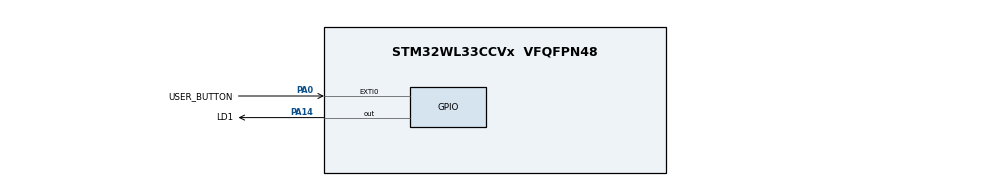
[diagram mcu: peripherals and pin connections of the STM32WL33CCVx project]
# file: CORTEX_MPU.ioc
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Mcu.Family=STM32WL3
Mcu.Name=STM32WL33CCVx
Mcu.Package=VFQFPN48
NVIC.GPIOA_IRQn=true\:0\:0\:false\:false\:true\:true\:true\:true
OSCIN.Mode=HSE-External-Oscillator
OSCIN.Signal=RCC_OSC_IN
OSCOUT.Mode=HSE-External-Oscillator
OSCOUT.Signal=RCC_OSC_OUT
PA0.GPIO_Label=USER_BUTTON
PA0.GPIO_ModeDefaultEXTI=GPIO_MODE_IT_FALLING
PA0.GPIO_PuPd=GPIO_PULLUP
PA0.Signal=GPXTI0
PA14.GPIO_Label=LD1
PA14.GPIO_ModeDefaultOutputPP=GPIO_MODE_OUTPUT_PP
PA14.GPIO_Speed=GPIO_SPEED_FREQ_VERY_HIGH
PA14.Signal=GPIO_Output
ProjectManager.HeapSize=0x000
ProjectManager.StackSize=0xC00
ProjectManager.TargetToolchain=EWARM V9.30
RCC.HSE_VALUE=48000000
RCC.HSI_VALUE=64000000
RCC.LSE_VALUE=32768
RCC.RC64MPLLSource=RCC_LSCOSOURCE_PLL64
VP_PWR_VS_SECSignals.Mode=Security/Privilege
board=custom

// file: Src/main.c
/* USER CODE BEGIN Header */
/**
  ******************************************************************************
  * @file    Examples_LL/CORTEX/CORTEX_MPU/Src/main.c
  * @author  MCD Application Team
  * @brief   This example presents the MPU features through
  *          the STM32WL3x CORTEX LL API.
  ******************************************************************************
  * @attention
  *
  * Copyright (c) 2024 STMicroelectronics.
  * All rights reserved.
  *
  * This software is licensed under terms that can be found in the LICENSE file
  * in the root directory of this software component.
  * If no LICENSE file comes with this software, it is provided AS-IS.
  *
  ******************************************************************************
  */
/* USER CODE END Header */
#include "main.h"

/* USER CODE BEGIN PD */

/* Address of the privileged read-only area */
#define ARRAY_ADDRESS_START                      (0x20002000UL)
/* Size of privileged read-only area */
#define ARRAY_SIZE                               LL_MPU_REGION_SIZE_512B
/* Region size to contain privileged read-only area */
#define REGION_SIZE                              LL_MPU_REGION_SIZE_256B
#define REGION_NUMBER                            LL_MPU_REGION_NUMBER3
#define EXAMPLE_RAM_ADDRESS_START                (0x20000000UL)
#define EXAMPLE_RAM_SIZE                         LL_MPU_REGION_SIZE_16KB
#define EXAMPLE_PERIPH_ADDRESS_START             (0x40000000)
#define EXAMPLE_PERIPH_SIZE                      LL_MPU_REGION_SIZE_512KB
#define EXAMPLE_FLASH_ADDRESS_START              (0x08000000)
#define EXAMPLE_FLASH_SIZE                       LL_MPU_REGION_SIZE_512KB
#define EXAMPLE_RAM_REGION_NUMBER                LL_MPU_REGION_NUMBER0
#define EXAMPLE_FLASH_REGION_NUMBER              LL_MPU_REGION_NUMBER1
#define EXAMPLE_PERIPH_REGION_NUMBER             LL_MPU_REGION_NUMBER2
#define portMPU_REGION_READ_WRITE                LL_MPU_REGION_FULL_ACCESS
#define portMPU_REGION_PRIVILEGED_READ_ONLY      LL_MPU_REGION_PRIV_RO
#define portMPU_REGION_READ_ONLY                 LL_MPU_REGION_PRIV_RO_URO
#define portMPU_REGION_PRIVILEGED_READ_WRITE     LL_MPU_REGION_PRIV_RW

/* USER CODE END PD */

/* USER CODE BEGIN PV */

__IO uint8_t ubButtonPress = 0;

#if defined ( __ICCARM__ )
#pragma location=ARRAY_ADDRESS_START
__no_init __IO uint8_t PrivilegedReadOnlyArray[ARRAY_SIZE];
#else
__IO uint8_t PrivilegedReadOnlyArray[ARRAY_SIZE] __attribute__((section(".ROarraySection")));
#endif

/* USER CODE END PV */

void SystemClock_Config(void);
void PeriphCommonClock_Config(void);
static void MX_GPIO_Init(void);
/* USER CODE BEGIN PFP */

void     Configure_MPU(void);
void     MPU_AccessPermConfig(void);
void LED_On(void);
void LED_Off(void);
void WaitForUserButtonPress(void);

/* USER CODE END PFP */

int main(void)
{

  /* MCU Configuration--------------------------------------------------------*/

  /* Reset of all peripherals, Initializes the Flash interface and the Systick. */
  LL_APB0_GRP1_EnableClock(LL_APB0_GRP1_PERIPH_SYSCFG);

  /* Configure the system clock */
  SystemClock_Config();

  /* Configure the peripherals common clocks */
  PeriphCommonClock_Config();

  /* Initialize all configured peripherals */
  MX_GPIO_Init();
  /* USER CODE BEGIN 2 */

  /* Set MPU regions */
  Configure_MPU();
  MPU_AccessPermConfig();

  /* Read from PrivilegedReadOnlyArray. This will not generate error */
  (void)PrivilegedReadOnlyArray[ARRAY_SIZE - 1];

  /* Toggle quickly LD1 while waiting for User-button press */
  WaitForUserButtonPress();

  /* Write into PrivilegedReadOnlyArray. This will generate memory fault error */
  PrivilegedReadOnlyArray[ARRAY_SIZE - 1] = 'e';

  /* USER CODE END 2 */

  /* Infinite loop */
  while (1)
  {

  }
}

void SystemClock_Config(void)
{

   /* Set HSE Capacitor Tuning */
  LL_RCC_HSE_SetCapacitorTuning(CFG_HW_RCC_HSE_CAPACITOR_TUNE);

   /* Set HSE startup Current */
 LL_RCC_HSE_SetStartupCurrent(0);

   /* Set HSE Amplitude Threshold */
 LL_RCC_HSE_SetAmplitudeThreshold(0);

   /* Set HSE Current Control */
  LL_RCC_HSE_SetCurrentControl(40);

   /* Enable the HSE */
  LL_RCC_HSE_Enable();

   /* Wait till HSE is ready */
  while(LL_RCC_HSE_IsReady() != 1)
  {
  }

  LL_FLASH_SetLatency(LL_FLASH_WAIT_STATES_1);

   /* Enable the RC64MPLL*/
  LL_RCC_RC64MPLL_Enable();

   /* Wait till RC64MPLL is ready */
  while(LL_RCC_RC64MPLL_IsReady() != 1)
  {
  }

  LL_RCC_SetRC64MPLLPrescaler(LL_RCC_RC64MPLL_DIV_1);

   /* Update the SystemCoreClock global variable */
  LL_SetSystemCoreClock(64000000);

   /* Configure the source of time base considering new system clocks settings*/
  LL_Init1msTick(64000000);
}

void PeriphCommonClock_Config(void)
{
  LL_RCC_SetSMPSPrescaler(LL_RCC_SMPS_DIV_2);

   /* Enable the KRM*/
  LL_RCC_KRM_Enable();
  LL_RCC_KRM_SetRateMultiplier(2);
}

static void MX_GPIO_Init(void)
{
  LL_GPIO_InitTypeDef GPIO_InitStruct = {0};

  /* GPIO Ports Clock Enable */
  LL_AHB1_GRP1_EnableClock(LL_AHB1_GRP1_PERIPH_GPIOA);

  /**/
  LL_GPIO_ResetOutputPin(LD1_GPIO_Port, LD1_Pin);

  /**/
  LL_GPIO_SetPinPull(USER_BUTTON_GPIO_Port, USER_BUTTON_Pin, LL_GPIO_PULL_UP);

  /**/
  LL_EXTI_EnableIT(LL_EXTI_LINE_PA0);

  /**/
  LL_GPIO_SetPinMode(USER_BUTTON_GPIO_Port, USER_BUTTON_Pin, LL_GPIO_MODE_INPUT);

  /**/
  GPIO_InitStruct.Pin = LD1_Pin;
  GPIO_InitStruct.Mode = LL_GPIO_MODE_OUTPUT;
  GPIO_InitStruct.Speed = LL_GPIO_SPEED_FREQ_VERY_HIGH;
  GPIO_InitStruct.OutputType = LL_GPIO_OUTPUT_PUSHPULL;
  GPIO_InitStruct.Pull = LL_GPIO_PULL_NO;
  LL_GPIO_Init(LD1_GPIO_Port, &GPIO_InitStruct);

  /* EXTI interrupt init*/
  NVIC_SetPriority(GPIOA_IRQn, 0);
  NVIC_EnableIRQ(GPIOA_IRQn);

  /* USER CODE BEGIN MX_GPIO_Init_2 */
   LL_EXTI_EnableIT(LL_EXTI_LINE_PA0);
   LL_GPIO_SetOutputPin(LD1_GPIO_Port, LD1_Pin);

  /* USER CODE END MX_GPIO_Init_2 */
}

/* USER CODE BEGIN 4 */

/**
  * @brief  Configures the main MPU regions.
  * @param  None
  * @retval None
  */
void Configure_MPU(void)
{
  /* Disable MPU */
  LL_MPU_Disable();

  /* Configure RAM region as Region Number 0, 16KB of size and R/W region */
  LL_MPU_ConfigRegion(EXAMPLE_RAM_REGION_NUMBER, 0x00, EXAMPLE_RAM_ADDRESS_START,
         EXAMPLE_RAM_SIZE | portMPU_REGION_READ_WRITE | LL_MPU_ACCESS_NOT_BUFFERABLE |
         LL_MPU_ACCESS_NOT_CACHEABLE | LL_MPU_ACCESS_NOT_SHAREABLE | LL_MPU_TEX_LEVEL0 |
         LL_MPU_INSTRUCTION_ACCESS_ENABLE);

  /* Configure FLASH region as REGION Number 1, 512KB of size and R/W region */
  LL_MPU_ConfigRegion(EXAMPLE_FLASH_REGION_NUMBER, 0x00, EXAMPLE_FLASH_ADDRESS_START,
         EXAMPLE_FLASH_SIZE | portMPU_REGION_READ_WRITE | LL_MPU_ACCESS_NOT_BUFFERABLE |
         LL_MPU_ACCESS_NOT_CACHEABLE | LL_MPU_ACCESS_NOT_SHAREABLE | LL_MPU_TEX_LEVEL0 |
         LL_MPU_INSTRUCTION_ACCESS_ENABLE);

  /* Configure Peripheral region as REGION Number 2, 255MB of size, R/W and Execute
  Never region */
  LL_MPU_ConfigRegion(EXAMPLE_PERIPH_REGION_NUMBER, 0x00, EXAMPLE_PERIPH_ADDRESS_START,
         EXAMPLE_PERIPH_SIZE | portMPU_REGION_READ_WRITE | LL_MPU_ACCESS_NOT_BUFFERABLE |
         LL_MPU_ACCESS_NOT_CACHEABLE | LL_MPU_ACCESS_NOT_SHAREABLE | LL_MPU_TEX_LEVEL0 |
         LL_MPU_INSTRUCTION_ACCESS_DISABLE);

  /* Enable MPU (any access not covered by any enabled region will cause a fault) */
  LL_MPU_Enable(LL_MPU_CTRL_PRIVILEGED_DEFAULT);
}

/**
  * @brief  This function configures the access right using Cortex-M0+ MPU regions.
  * @param  None
  * @retval None
  */
void MPU_AccessPermConfig(void)
{
  /* Configure region for PrivilegedReadOnlyArray as REGION Number 3, 32byte and R
     only in privileged mode */
  /* Disable MPU */
  LL_MPU_Disable();

  LL_MPU_ConfigRegion(REGION_NUMBER, 0x00, ARRAY_ADDRESS_START,
         REGION_SIZE | portMPU_REGION_PRIVILEGED_READ_ONLY | LL_MPU_ACCESS_NOT_BUFFERABLE |
         LL_MPU_ACCESS_NOT_CACHEABLE | LL_MPU_ACCESS_NOT_SHAREABLE | LL_MPU_TEX_LEVEL0 |
         LL_MPU_INSTRUCTION_ACCESS_ENABLE);

  /* Enable MPU (any access not covered by any enabled region will cause a fault) */
  LL_MPU_Enable(LL_MPU_CTRL_PRIVILEGED_DEFAULT);
}

/**
  * @brief  Turn on LD1.
  * @param  None
  * @retval None
  */
void LED_On(void)
{
  /* Turn LD1 on */
  LL_GPIO_SetOutputPin(LD1_GPIO_Port, LD1_Pin);
}

/**
  * @brief  Turn off LD1.
  * @param  None
  * @retval None
  */
void LED_Off(void)
{
  /* Turn LD1 off */
  LL_GPIO_ResetOutputPin(LD1_GPIO_Port, LD1_Pin);
}

/**
  * @brief  Wait for USER push-button press and toggle LD1.
  * @param  None
  * @retval None
  */
/*  */
void WaitForUserButtonPress(void)
{
  while (ubButtonPress == 0)
  {
    LL_GPIO_TogglePin(LD1_GPIO_Port, LD1_Pin);
    LL_mDelay(LED_BLINK_FAST);
  }
  /* Turn LD1 off */
  LED_Off();
}

/******************************************************************************/
/*   USER IRQ HANDLER TREATMENT                                               */
/******************************************************************************/
/**
  * @brief  Function to manage User button IRQ Handler
  * @param  None
  * @retval None
  */
void UserButton_Callback(void)
{
  /* Update USER push-button variable : to be checked in waiting loop in main program */
  ubButtonPress = 1;
}

/* USER CODE END 4 */

void Error_Handler(void)
{
  while (1)
  {
  }
}
